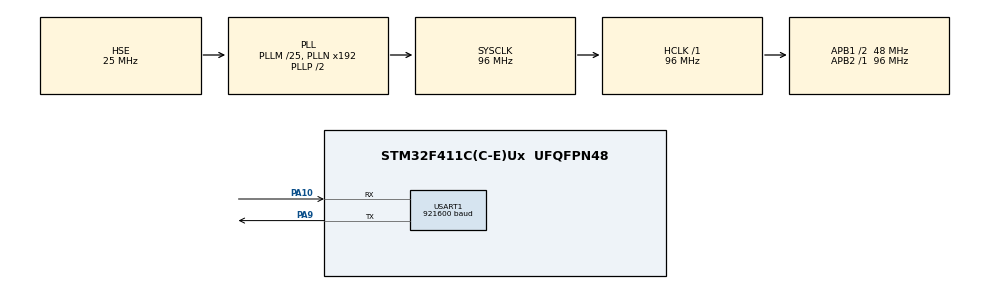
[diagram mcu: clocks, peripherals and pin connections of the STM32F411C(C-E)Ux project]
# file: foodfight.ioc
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FREERTOS.Mutexes01=oneMutex,Dynamic,NULL
FREERTOS.Queues01=infoQueue,16,uint8_t,0,Dynamic,NULL,NULL
FREERTOS.Tasks01=defaultTask,24,128,StartDefaultTask,Default,NULL,Dynamic,NULL,NULL
FREERTOS.configUSE_NEWLIB_REENTRANT=1
Mcu.Family=STM32F4
Mcu.Name=STM32F411C(C-E)Ux
Mcu.Package=UFQFPN48
NVIC.PriorityGroup=NVIC_PRIORITYGROUP_4
NVIC.TIM1_TRG_COM_TIM11_IRQn=true\:15\:0\:false\:false\:true\:false\:false\:true\:true
NVIC.TimeBase=TIM1_TRG_COM_TIM11_IRQn
NVIC.TimeBaseIP=TIM11
PA10.Mode=Asynchronous
PA10.Signal=USART1_RX
PA13.Mode=Serial_Wire
PA13.Signal=SYS_JTMS-SWDIO
PA14.Mode=Serial_Wire
PA14.Signal=SYS_JTCK-SWCLK
PA9.Mode=Asynchronous
PA9.Signal=USART1_TX
PH0\ -\ OSC_IN.Mode=HSE-External-Oscillator
PH0\ -\ OSC_IN.Signal=RCC_OSC_IN
PH1\ -\ OSC_OUT.Mode=HSE-External-Oscillator
PH1\ -\ OSC_OUT.Signal=RCC_OSC_OUT
ProjectManager.HeapSize=0x200
ProjectManager.StackSize=0x400
ProjectManager.TargetToolchain=STM32CubeIDE
RCC.48MHZClocksFreq_Value=48000000
RCC.AHBFreq_Value=96000000
RCC.APB1CLKDivider=RCC_HCLK_DIV2
RCC.APB1Freq_Value=48000000
RCC.APB1TimFreq_Value=96000000
RCC.APB2Freq_Value=96000000
RCC.APB2TimFreq_Value=96000000
RCC.CortexFreq_Value=96000000
RCC.HCLKFreq_Value=96000000
RCC.HSE_VALUE=25000000
RCC.HSI_VALUE=16000000
RCC.LSE_VALUE=32768
RCC.PLLM=25
RCC.PLLSourceVirtual=RCC_PLLSOURCE_HSE
RCC.SYSCLKFreq_VALUE=96000000
RCC.SYSCLKSource=RCC_SYSCLKSOURCE_PLLCLK
RCC.VCOOutputFreq_Value=192000000
USART1.BaudRate=921600
USART1.VirtualMode=VM_ASYNC
VP_FREERTOS_VS_CMSIS_V2.Mode=CMSIS_V2
VP_SYS_VS_tim11.Mode=TIM11
board=custom

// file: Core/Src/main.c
/* USER CODE BEGIN Header */
/**
  ******************************************************************************
  * @file           : main.c
  * @brief          : Main program body
  ******************************************************************************
  * @attention
  *
  * <h2><center>&copy; Copyright (c) 2021 STMicroelectronics.
  * All rights reserved.</center></h2>
  *
  * This software component is licensed by ST under BSD 3-Clause license,
  * the "License"; You may not use this file except in compliance with the
  * License. You may obtain a copy of the License at:
  *                        opensource.org/licenses/BSD-3-Clause
  *
  ******************************************************************************
  */
/* USER CODE END Header */
#include "main.h"
#include "cmsis_os.h"

/* USER CODE BEGIN Includes */
#include "stdio.h"
#include "string.h"
/* USER CODE END Includes */

UART_HandleTypeDef huart1;

/* Definitions for defaultTask */
osThreadId_t defaultTaskHandle;
const osThreadAttr_t defaultTask_attributes = {
  .name = "defaultTask",
  .stack_size = 128 * 4,
  .priority = (osPriority_t) osPriorityNormal,
};
/* Definitions for infoQueue */
osMessageQueueId_t infoQueueHandle;
const osMessageQueueAttr_t infoQueue_attributes = {
  .name = "infoQueue"
};
/* Definitions for oneMutex */
osMutexId_t oneMutexHandle;
const osMutexAttr_t oneMutex_attributes = {
  .name = "oneMutex"
};
/* USER CODE BEGIN PV */

osThreadId_t fightTaskHandle[10];
const osThreadAttr_t fightTask_attributes = {
  .name = "fightTask",
  .stack_size = 128 * 4,
  .priority = (osPriority_t) osPriorityLow,
};

/* USER CODE END PV */

void SystemClock_Config(void);
static void MX_GPIO_Init(void);
static void MX_USART1_UART_Init(void);
void StartDefaultTask(void *argument);

/* USER CODE BEGIN 0 */

// Send printf to uart1
int _write(int fd, char* ptr, int len) {
  HAL_StatusTypeDef hstatus;

  if (fd == 1 || fd == 2) {
    hstatus = HAL_UART_Transmit(&huart1, (uint8_t *) ptr, len, HAL_MAX_DELAY);
    if (hstatus == HAL_OK)
      return len;
    else
      return -1;
  }
  return -1;
}

void StartFightTask(void *argument)
{
  /* USER CODE BEGIN 5 */

	uint32_t fightTaskId = (uint32_t)argument;
	uint32_t mutexCount = 0;

	osDelay(fightTaskId);
	DBG("FT Starting %lu", fightTaskId);
	osDelay(10);

  /* Infinite loop */
  for(;;)
  {
	DBG("FT %lu Trying to acquire mutex", fightTaskId); osThreadYield();
	uint32_t startTick = osKernelGetTickCount();
	osStatus_t mutex = osMutexAcquire(oneMutexHandle, osWaitForever);
	if (mutex == osOK) {
		mutexCount++;
		DBG("FT %lu got mutex number %lu, waited %lus", fightTaskId, mutexCount, (osKernelGetTickCount() - startTick) / 1000); osThreadYield();
		osMessageQueuePut(infoQueueHandle, &fightTaskId, 0, osWaitForever);
		osDelay(1000);
		DBG("FT %lu releasing mutex", fightTaskId); osThreadYield();
		osMutexRelease(oneMutexHandle);
	}
	osThreadYield();
  }
  /* USER CODE END 5 */
}

/* USER CODE END 0 */

int main(void)
{

  /* MCU Configuration--------------------------------------------------------*/

  /* Reset of all peripherals, Initializes the Flash interface and the Systick. */
  HAL_Init();

  /* Configure the system clock */
  SystemClock_Config();

  /* Initialize all configured peripherals */
  MX_GPIO_Init();
  MX_USART1_UART_Init();

  /* Init scheduler */
  osKernelInitialize();
  /* Create the mutex(es) */
  /* creation of oneMutex */
  oneMutexHandle = osMutexNew(&oneMutex_attributes);

  /* Create the queue(s) */
  /* creation of infoQueue */
  infoQueueHandle = osMessageQueueNew (16, sizeof(uint8_t), &infoQueue_attributes);

  /* Create the thread(s) */
  /* creation of defaultTask */
  defaultTaskHandle = osThreadNew(StartDefaultTask, NULL, &defaultTask_attributes);

  /* USER CODE BEGIN RTOS_THREADS */
  /* add threads, ... */
  for (uint32_t i = 0; i < sizeof(fightTaskHandle) / sizeof(fightTaskHandle[0]); i++) {
	  fightTaskHandle[i] = osThreadNew(StartFightTask, (uint32_t *)i, &fightTask_attributes);
  }
  /* USER CODE END RTOS_THREADS */

  /* Start scheduler */
  osKernelStart();

  /* We should never get here as control is now taken by the scheduler */
  /* Infinite loop */
  while (1)
  {

  }
}

void SystemClock_Config(void)
{
  RCC_OscInitTypeDef RCC_OscInitStruct = {0};
  RCC_ClkInitTypeDef RCC_ClkInitStruct = {0};

  /** Configure the main internal regulator output voltage
  */
  __HAL_RCC_PWR_CLK_ENABLE();
  __HAL_PWR_VOLTAGESCALING_CONFIG(PWR_REGULATOR_VOLTAGE_SCALE1);

  /** Initializes the RCC Oscillators according to the specified parameters
  * in the RCC_OscInitTypeDef structure.
  */
  RCC_OscInitStruct.OscillatorType = RCC_OSCILLATORTYPE_HSE;
  RCC_OscInitStruct.HSEState = RCC_HSE_ON;
  RCC_OscInitStruct.PLL.PLLState = RCC_PLL_ON;
  RCC_OscInitStruct.PLL.PLLSource = RCC_PLLSOURCE_HSE;
  RCC_OscInitStruct.PLL.PLLM = 25;
  RCC_OscInitStruct.PLL.PLLN = 192;
  RCC_OscInitStruct.PLL.PLLP = RCC_PLLP_DIV2;
  RCC_OscInitStruct.PLL.PLLQ = 4;
  if (HAL_RCC_OscConfig(&RCC_OscInitStruct) != HAL_OK)
  {
    Error_Handler();
  }

  /** Initializes the CPU, AHB and APB buses clocks
  */
  RCC_ClkInitStruct.ClockType = RCC_CLOCKTYPE_HCLK|RCC_CLOCKTYPE_SYSCLK
                              |RCC_CLOCKTYPE_PCLK1|RCC_CLOCKTYPE_PCLK2;
  RCC_ClkInitStruct.SYSCLKSource = RCC_SYSCLKSOURCE_PLLCLK;
  RCC_ClkInitStruct.AHBCLKDivider = RCC_SYSCLK_DIV1;
  RCC_ClkInitStruct.APB1CLKDivider = RCC_HCLK_DIV2;
  RCC_ClkInitStruct.APB2CLKDivider = RCC_HCLK_DIV1;

  if (HAL_RCC_ClockConfig(&RCC_ClkInitStruct, FLASH_LATENCY_3) != HAL_OK)
  {
    Error_Handler();
  }
}

static void MX_USART1_UART_Init(void)
{

  huart1.Instance = USART1;
  huart1.Init.BaudRate = 921600;
  huart1.Init.WordLength = UART_WORDLENGTH_8B;
  huart1.Init.StopBits = UART_STOPBITS_1;
  huart1.Init.Parity = UART_PARITY_NONE;
  huart1.Init.Mode = UART_MODE_TX_RX;
  huart1.Init.HwFlowCtl = UART_HWCONTROL_NONE;
  huart1.Init.OverSampling = UART_OVERSAMPLING_16;
  if (HAL_UART_Init(&huart1) != HAL_OK)
  {
    Error_Handler();
  }

}

static void MX_GPIO_Init(void)
{

  /* GPIO Ports Clock Enable */
  __HAL_RCC_GPIOH_CLK_ENABLE();
  __HAL_RCC_GPIOA_CLK_ENABLE();

}

void StartDefaultTask(void *argument)
{
  /* USER CODE BEGIN 5 */

	uint32_t fightTaskId = (uint32_t)argument;
	uint32_t mutexCount = 0;

	osDelay(fightTaskId);
	DBG("FT Starting %lu", fightTaskId);
	osDelay(10);

  /* Infinite loop */
  for(;;)
  {
	DBG("FT %lu Trying to acquire mutex", fightTaskId); osThreadYield();
	uint32_t startTick = osKernelGetTickCount();
	osStatus_t mutex = osMutexAcquire(oneMutexHandle, osWaitForever);
	if (mutex == osOK) {
		mutexCount++;
		DBG("FT %lu got mutex number %lu, waited %lus", fightTaskId, mutexCount, (osKernelGetTickCount() - startTick) / 1000); osThreadYield();
		osMessageQueuePut(infoQueueHandle, &fightTaskId, 0, osWaitForever);
		osDelay(1000);
		DBG("FT %lu releasing mutex", fightTaskId); osThreadYield();
		osMutexRelease(oneMutexHandle);
	}
	osThreadYield();
  }
  /* USER CODE END 5 */
}

void HAL_TIM_PeriodElapsedCallback(TIM_HandleTypeDef *htim)
{
  if (htim->Instance == TIM11) {
    HAL_IncTick();
  }
}

void Error_Handler(void)
{
  __disable_irq();
  while (1)
  {
  }
}
